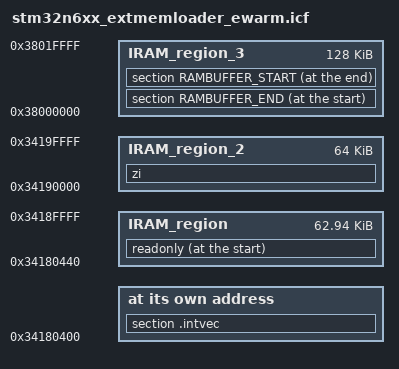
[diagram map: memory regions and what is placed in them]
/*###ICF### Section handled by ICF editor, don't touch! ****/
/*-Editor annotation file-*/
/* IcfEditorFile="$TOOLKIT_DIR$\config\ide\IcfEditor\cortex_v1_1.xml" */
/*-Specials-*/
define symbol __ICFEDIT_intvec_start__ = 0x34180400;

/*-Memory Regions-*/
define symbol __ICFEDIT_region_RAM_start__  = 0x34180440;
define symbol __ICFEDIT_region_RAM_end__    = 0x3418FFFF;
define symbol __ICFEDIT_region_IRAM2_start__ = 0x34190000;
define symbol __ICFEDIT_region_IRAM2_end__   = 0x3419FFFF;

export symbol __ICFEDIT_region_RAM_end__;

define symbol __ICFEDIT_region_IRAM3_start__  = 0x38000000;
define symbol __ICFEDIT_region_IRAM3_end__    = 0x3801FFFF;

/*-Sizes-*/
define symbol __ICFEDIT_size_cstack__ = 0x400;
define symbol __ICFEDIT_size_heap__   = 0x8;    /* not used defined the min size */
/**** End of ICF editor section. ###ICF###*/

define memory mem with size = 4G;
define region IRAM_region   =   mem:[from __ICFEDIT_region_RAM_start__ to __ICFEDIT_region_RAM_end__];
define region IRAM_region_2 =   mem:[from __ICFEDIT_region_IRAM2_start__ to __ICFEDIT_region_IRAM2_end__];
define region IRAM_region_3 =   mem:[from __ICFEDIT_region_IRAM3_start__ to __ICFEDIT_region_IRAM3_end__];
define block CSTACK    with alignment = 8, size = __ICFEDIT_size_cstack__   { };
define block HEAP      with alignment = 8, size = __ICFEDIT_size_heap__     { };

do not initialize { readwrite };
do not initialize  { section .noinit };

place at address mem:__ICFEDIT_intvec_start__ { section .intvec };
place at start of IRAM_region { readonly };
place in IRAM_region          { block RamTop with fixed order { readwrite, block CSTACK, block HEAP }};
place in IRAM_region_2        { zi};
place at start of IRAM_region_3 { section RAMBUFFER_END };
place at end of IRAM_region_3   { section RAMBUFFER_START };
